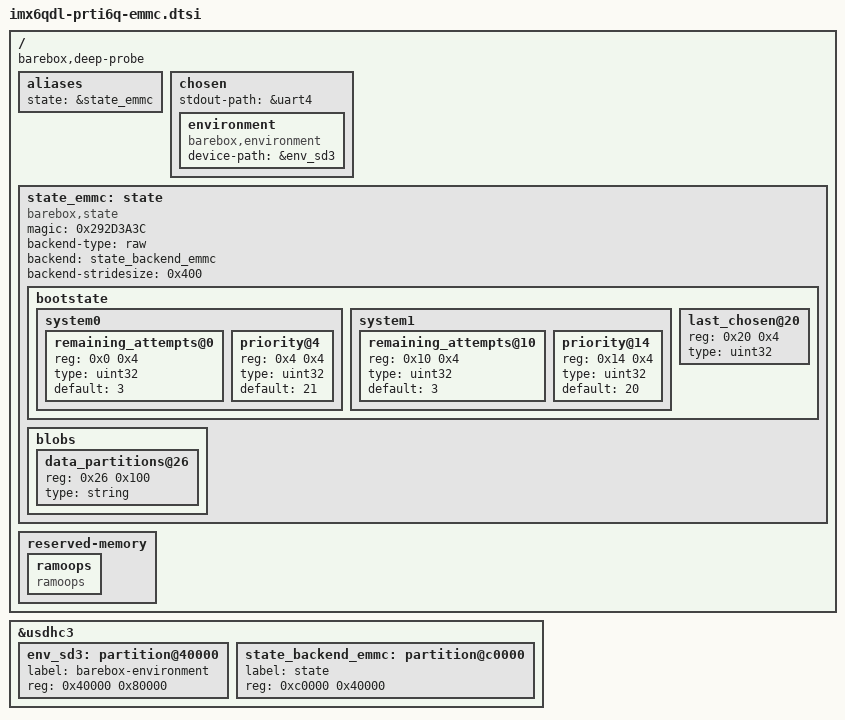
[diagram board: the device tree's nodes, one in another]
// SPDX-License-Identifier: GPL-2.0-or-later OR MIT

/ {
	barebox,deep-probe;

	aliases {
		state = &state_emmc;
	};

	chosen {
		stdout-path = &uart4;

		environment {
			compatible = "barebox,environment";
			device-path = &env_sd3;
		};
	};

	state_emmc: state {
		magic = <0x292D3A3C>;
		compatible = "barebox,state";
		backend-type = "raw";
		backend = <&state_backend_emmc>;
		backend-stridesize = <0x400>;

		bootstate {
			#address-cells = <1>;
			#size-cells = <1>;

			system0 {
				#address-cells = <1>;
				#size-cells = <1>;

				remaining_attempts@0 {
					reg = <0x0 0x4>;
					type = "uint32";
					default = <3>;
				};

				priority@4 {
					reg = <0x4 0x4>;
					type = "uint32";
					default = <21>;
				};
			};

			system1 {
				#address-cells = <1>;
				#size-cells = <1>;

				remaining_attempts@10 {
					reg = <0x10 0x4>;
					type = "uint32";
					default = <3>;
				};

				priority@14 {
					reg = <0x14 0x4>;
					type = "uint32";
					default = <20>;
				};
			};

			last_chosen@20 {
				reg = <0x20 0x4>;
				type = "uint32";
			};
		};

		blobs {
			#address-cells = <1>;
			#size-cells = <1>;

			data_partitions@26 {
				reg = <0x26 0x100>;
				type = "string";
			};
		};
	};

	reserved-memory {
		#address-cells = <1>;
		#size-cells = <1>;
		ranges;

		/* Address will be determined by the bootloader */
		ramoops {
			compatible = "ramoops";
		};
	};
};

&usdhc3 {
	#address-cells = <1>;
	#size-cells = <1>;

	env_sd3: partition@40000 {
		label = "barebox-environment";
		reg = <0x40000 0x80000>;
	};

	state_backend_emmc: partition@c0000 {
		label = "state";
		reg = <0xc0000 0x40000>;
	};
};
